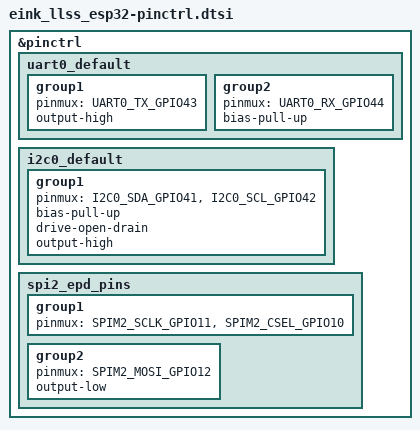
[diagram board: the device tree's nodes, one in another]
#include <zephyr/dt-bindings/pinctrl/esp-pinctrl-common.h>
#include <dt-bindings/pinctrl/esp32s3-pinctrl.h>
#include <zephyr/dt-bindings/pinctrl/esp32s3-gpio-sigmap.h>

&pinctrl {
	uart0_default: uart0_default {
		group1 {
			pinmux = <UART0_TX_GPIO43>;
			output-high;
		};

		group2 {
			pinmux = <UART0_RX_GPIO44>;
			bias-pull-up;
		};
	};

	i2c0_default: i2c0_default {
		group1 {
			pinmux = <I2C0_SDA_GPIO41>,
				 <I2C0_SCL_GPIO42>;
			bias-pull-up;
			drive-open-drain;
			output-high;
		};
	};

	spi2_epd_pins: spi2_epd_pins {
		group1 {
			pinmux = <SPIM2_SCLK_GPIO11>,
				 <SPIM2_CSEL_GPIO10>;
		};

		group2 {
			pinmux = <SPIM2_MOSI_GPIO12>;
			output-low;
		};
	};
};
